# STM32U599xx register map
File version: 1.0
Registers are 32-bit, read-write, reset 0x0 unless marked. A register's access mark holds for its fields unless they carry their own. Offsets are from the block's base; [hi:lo] are bit positions; 'fields as' and 'values as' point back to an identical list.

## FMC_Bank3_R — Flexible Memory Controller Bank3
Base 0x420D0480
Same registers: FMC_Bank3_R_S 0x520D0480
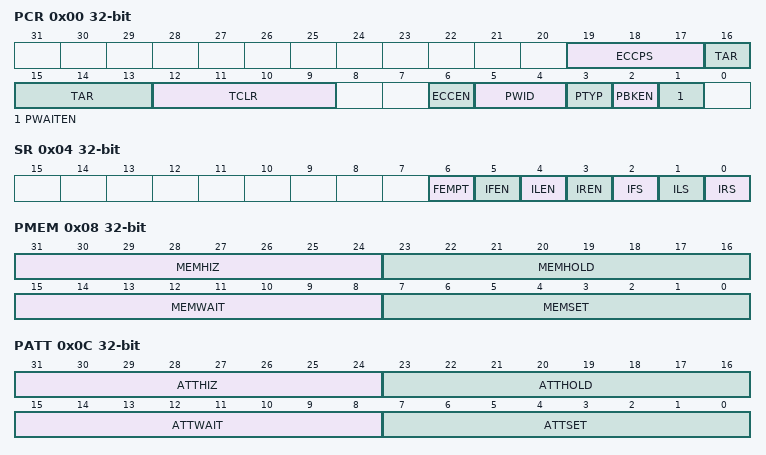
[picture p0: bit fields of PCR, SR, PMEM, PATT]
0x00 PCR — NAND Flash control register
  [19:17] ECCPS — ECCPS[1:0] bits (ECC page size)
  [16:13] TAR — TAR[3:0] bits (ALE to RE delay)
  [12:9] TCLR — TCLR[3:0] bits (CLE to RE delay)
  [6] ECCEN — ECC computation logic enable bit
  [5:4] PWID — PWID[1:0] bits (NAND Flash databus width)
  [3] PTYP — Memory type
  [2] PBKEN — NAND Flash memory bank enable bit
  [1] PWAITEN — Wait feature enable bit
0x04 SR — NAND Flash FIFO status and interrupt register
  [6] FEMPT — FIFO empty
  [5] IFEN — Interrupt Falling Edge detection Enable bit
  [4] ILEN — Interrupt Level detection Enable bit
  [3] IREN — Interrupt Rising Edge detection Enable bit
  [2] IFS — Interrupt Falling Edge status
  [1] ILS — Interrupt Level status
  [0] IRS — Interrupt Rising Edge status
0x08 PMEM — NAND Flash Common memory space timing register
  [31:24] MEMHIZ — MEMHIZ[7:0] bits (Common memory databus HiZ time)
  [23:16] MEMHOLD — MEMHOLD[7:0] bits (Common memory hold time)
  [15:8] MEMWAIT — MEMWAIT[7:0] bits (Common memory wait time)
  [7:0] MEMSET — MEMSET[7:0] bits (Common memory setup time)
0x0C PATT — NAND Flash Attribute memory space timing register
  [31:24] ATTHIZ — ATTHIZ[7:0] bits (Attribute memory databus HiZ time)
  [23:16] ATTHOLD — ATTHOLD[7:0] bits (Attribute memory hold time)
  [15:8] ATTWAIT — ATTWAIT[7:0] bits (Attribute memory wait time)
  [7:0] ATTSET — ATTSET[7:0] bits (Attribute memory setup time)
0x14 ECCR — NAND Flash ECC result registers

## FMC_Bank1E_R — Flexible Memory Controller Bank1E
Base 0x420D0504
Same registers: FMC_Bank1E_R_S 0x520D0504
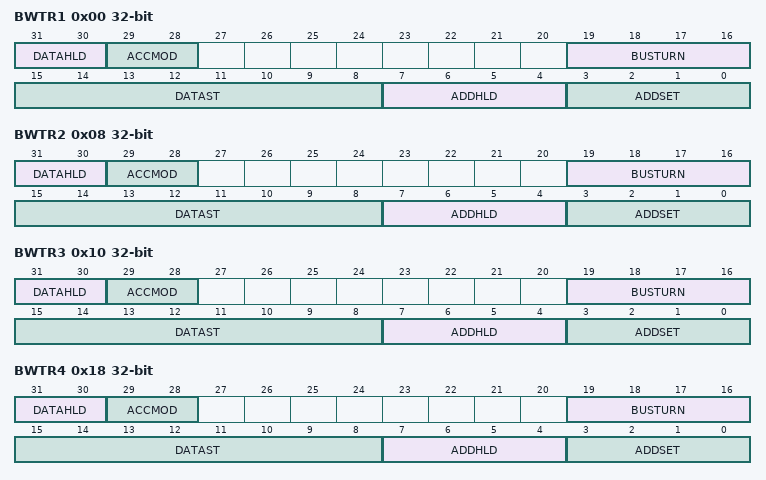
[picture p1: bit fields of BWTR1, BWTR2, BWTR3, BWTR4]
0x00 BWTR1 — NOR/PSRAM write timing registers
  [31:30] DATAHLD — DATAHLD[1:0] bits (Data hold phase duration)
  [29:28] ACCMOD — ACCMOD[1:0] bits (Access mode)
  [19:16] BUSTURN — BUSTURN[3:0] bits (Bus turnaround phase duration)
  [15:8] DATAST — DATAST [3:0] bits (Data-phase duration)
  [7:4] ADDHLD — ADDHLD[3:0] bits (Address-hold phase duration)
  [3:0] ADDSET — ADDSET[3:0] bits (Address setup phase duration)
0x08 BWTR2 — NOR/PSRAM write timing registers
  fields as BWTR1
0x10 BWTR3 — NOR/PSRAM write timing registers
  fields as BWTR1
0x18 BWTR4 — NOR/PSRAM write timing registers
  fields as BWTR1

## OPAMP12_COMMON
Base 0x46005000
Same registers: OPAMP12_COMMON_S 0x56005000
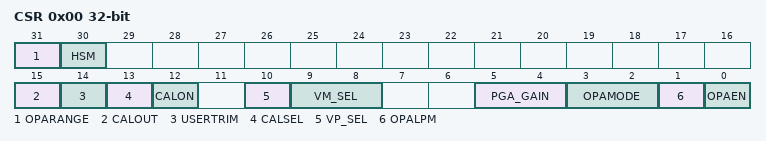
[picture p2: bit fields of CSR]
0x00 CSR — OPAMP control/status register, used for bits common to several OPAMP instances
  [31] OPARANGE — Operational amplifier range setting
    0=LOW (Power supply range low); 1=HIGH (Power supply range high - recommended for performance purpose)
  [30] HSM — Operational amplifier high speed mode
  [15] CALOUT — Operational amplifier calibration output
  [14] USERTRIM — User trimming enable
    0=FACTORY (OPAMP trimming factors set to factory values); 1=USER (OPAMP trimming factors set to user values)
  [13] CALSEL — Calibration selection
  [12] CALON — Calibration mode enable
    0=FUNCTIONAL (OPAMP functional mode); 1=CALIBRATION (OPAMP calibration mode)
  [10] VP_SEL — Non inverted input selection
    0=IO0 (OPAMP non inverting input connected to GPIO pin (pin PA0 for OPAMP1, pin PA6 for OPAMP2)); 1=DAC (OPAMP non inverting input connected to DAC1 channel output(channel1 for OPAMP1, channel2 for OPAMP2))
  [9:8] VM_SEL — Inverting input selection
    0=IO0 (OPAMP inverting input connected to GPIO pin (valid also in PGA mode for filtering). Note: OPAMP inverting input is used with OPAMP in mode standalone or PGA with external capacitors for filtering circuit. Otherwise (OPAMP in mode follower), OPAMP inverting input is not used (not connected to GPIO pin).); 1=IO1 (OPAMP inverting input (low leakage input) connected to GPIO pin (available only on package BGA132). Note: OPAMP inverting input is used with OPAMP in mode standalone or PGA with external capacitors for filtering circuit. Otherwise (OPAMP in mode follower), OPAMP inverting input is not used (not connected to GPIO pin).); 2=CONNECT_NO (OPAMP inverting input not externally connected (intended for OPAMP in mode follower or PGA without external capacitors for filtering))
  [5:4] PGA_GAIN — Operational amplifier Programmable amplifier gain value
    0=GAIN_2 (OPAMP PGA gain 2); 1=GAIN_4 (OPAMP PGA gain 4); 2=GAIN_8 (OPAMP PGA gain 8); 3=GAIN_16 (OPAMP PGA gain 16)
  [3:2] OPAMODE — Operational amplifier PGA mode
    0=STANDALONE (OPAMP functional mode, OPAMP operation in standalone); 3=FOLLOWER (OPAMP functional mode, OPAMP operation in follower); 2=PGA (OPAMP functional mode, OPAMP operation in PGA)
  [1] OPALPM — Operational amplifier Low Power Mode
  [0] OPAEN — OPAMP enable
